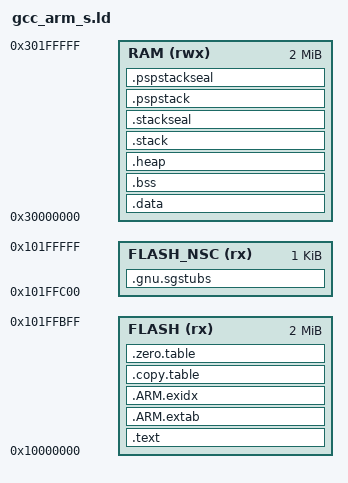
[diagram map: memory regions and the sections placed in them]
/*
 *
 * MIT License
 * Copyright (c) 2023 ARM Limited.
 *
 * SPDX-License-Identifier: MIT
 *
 * Permission is hereby granted, free of charge, to any person obtaining a copy
 * of this software and associated documentation files (the "Software"), to deal
 * in the Software without restriction, including without limitation the rights
 * to use, copy, modify, merge, publish, distribute, sublicense, and/or sell
 * copies of the Software, and to permit persons to whom the Software is
 * furnished to do so, subject to the following conditions:
 *
 * The above copyright notice and this permission notice shall be included in all
 * copies or substantial portions of the Software.
 *
 * THE SOFTWARE IS PROVIDED "AS IS", WITHOUT WARRANTY OF ANY KIND, EXPRESS OR
 * IMPLIED, INCLUDING BUT NOT LIMITED TO THE WARRANTIES OF MERCHANTABILITY,
 * FITNESS FOR A PARTICULAR PURPOSE AND NONINFRINGEMENT. IN NO EVENT SHALL THE
 * AUTHORS OR COPYRIGHT HOLDERS BE LIABLE FOR ANY CLAIM, DAMAGES OR OTHER
 * LIABILITY, WHETHER IN AN ACTION OF CONTRACT, TORT OR OTHERWISE, ARISING FROM,
 * OUT OF OR IN CONNECTION WITH THE SOFTWARE OR THE USE OR OTHER DEALINGS IN THE
 * SOFTWARE.
 *
 */

/*
 *-------- <<< Use Configuration Wizard in Context Menu >>> -------------------
 */

/*---------------------- Flash Configuration ----------------------------------
  <h> Flash Configuration
    <o0> Flash Base Address <0x0-0xFFFFFFFF:8>
    <o1> Flash Size (in Bytes) <0x0-0xFFFFFFFF:8>
  </h>
  -----------------------------------------------------------------------------*/
__ROM_BASE_S = 0x10000000;      
__ROM_SIZE_S = 0x001FFC00;      

__ROM_BASE_NSC =  0x101FFC00;      
__ROM_SIZE_NSC =  0x400;     

/*--------------------- Embedded RAM Configuration ----------------------------
  <h> RAM Configuration
    <o0> RAM Base Address    <0x0-0xFFFFFFFF:8>
    <o1> RAM Size (in Bytes) <0x0-0xFFFFFFFF:8>
  </h>
 -----------------------------------------------------------------------------*/
__RAM_BASE_S = 0x30000000;
__RAM_SIZE_S = 0x00200000;

/*--------------------- Stack / Heap Configuration ----------------------------
  <h> Stack / Heap Configuration
    <o0> Stack Size (in Bytes) <0x0-0xFFFFFFFF:8>
    <o1> Heap Size (in Bytes) <0x0-0xFFFFFFFF:8>
  </h>
  -----------------------------------------------------------------------------*/
__STACK_SIZE = 0x00000400;
__HEAP_SIZE  = 0x00000C00;
__PSP_STACK_SIZE = 0x00000400;


/*
 *-------------------- <<< end of configuration section >>> -------------------
 */

/* ARMv8-M stack sealing:
   to use ARMv8-M stack sealing set __STACKSEAL_SIZE to 8 otherwise keep 0
 */
__STACKSEAL_SIZE = 8;


MEMORY
{
  FLASH (rx)  : ORIGIN = __ROM_BASE_S, LENGTH = __ROM_SIZE_S
  FLASH_NSC (rx)  : ORIGIN = __ROM_BASE_NSC, LENGTH = __ROM_SIZE_NSC
  RAM   (rwx) : ORIGIN = __RAM_BASE_S, LENGTH = __RAM_SIZE_S
}

/* Linker script to place sections and symbol values. Should be used together
 * with other linker script that defines memory regions FLASH and RAM.
 * It references following symbols, which must be defined in code:
 *   Reset_Handler : Entry of reset handler
 *
 * It defines following symbols, which code can use without definition:
 *   __exidx_start
 *   __exidx_end
 *   __copy_table_start__
 *   __copy_table_end__
 *   __zero_table_start__
 *   __zero_table_end__
 *   __etext
 *   __data_start__
 *   __preinit_array_start
 *   __preinit_array_end
 *   __init_array_start
 *   __init_array_end
 *   __fini_array_start
 *   __fini_array_end
 *   __data_end__
 *   __bss_start__
 *   __bss_end__
 *   __end__
 *   end
 *   __HeapLimit
 *   __StackLimit
 *   __StackTop
 *   __stack
 *   __StackSeal      (only if ARMv8-M stack sealing is used)
 */
ENTRY(Reset_Handler)

SECTIONS
{
    .text :
    {
    
    KEEP(*(.vectors))
    *(.text*)

    KEEP(*(.init))
    KEEP(*(.fini))

    /* .ctors */
    *crtbegin.o(.ctors)
    *crtbegin?.o(.ctors)
    *(EXCLUDE_FILE(*crtend?.o *crtend.o) .ctors)
    *(SORT(.ctors.*))
    *(.ctors)

    /* .dtors */
    *crtbegin.o(.dtors)
    *crtbegin?.o(.dtors)
    *(EXCLUDE_FILE(*crtend?.o *crtend.o) .dtors)
    *(SORT(.dtors.*))
    *(.dtors)

    *(.rodata*)

    KEEP(*(.eh_frame*))
  } > FLASH

  /*
   * SG veneers:
   * All SG veneers are placed in the special output section .gnu.sgstubs. Its start address
   * must be set, either with the command line option С--section-startТ or in a linker script,
   * to indicate where to place these veneers in memory.
   */

  .gnu.sgstubs :
  {
    . = ALIGN(32);
    *(.gnu.sgstubs*)   /* Secure Gateway stubs */
  } > FLASH_NSC            /*FLASH*/
  
  Image$$ER_CMSE_VENEER$$Base = ADDR(.gnu.sgstubs);
  Image$$ER_CMSE_VENEER$$Limit = ADDR(.gnu.sgstubs) + SIZEOF(.gnu.sgstubs); 

  .ARM.extab :
  {
    *(.ARM.extab* .gnu.linkonce.armextab.*)
  } > FLASH

  __exidx_start = .;
  .ARM.exidx :
  {
    *(.ARM.exidx* .gnu.linkonce.armexidx.*)
  } > FLASH
  __exidx_end = .;

  .copy.table :
  {
    . = ALIGN(4);
    __copy_table_start__ = .;
    LONG (__etext)
    LONG (__data_start__)
    LONG (__data_end__ - __data_start__)
    /* Add each additional data section here */
    __copy_table_end__ = .;
  } > FLASH

  .zero.table :
  {
    . = ALIGN(4);
    __zero_table_start__ = .;
    /* Add each additional bss section here */
    __zero_table_end__ = .;
  } > FLASH

  /**
   * Location counter can end up 2byte aligned with narrow Thumb code but
   * __etext is assumed by startup code to be the LMA of a section in RAM
   * which must be 4byte aligned 
   */
  __etext = ALIGN (4);

  .data : AT (__etext)
  {
    __data_start__ = .;
    *(vtable)
    *(.data*)

    . = ALIGN(4);
    /* preinit data */
    PROVIDE_HIDDEN (__preinit_array_start = .);
    KEEP(*(.preinit_array))
    PROVIDE_HIDDEN (__preinit_array_end = .);

    . = ALIGN(4);
    /* init data */
    PROVIDE_HIDDEN (__init_array_start = .);
    KEEP(*(SORT(.init_array.*)))
    KEEP(*(.init_array))
    PROVIDE_HIDDEN (__init_array_end = .);


    . = ALIGN(4);
    /* finit data */
    PROVIDE_HIDDEN (__fini_array_start = .);
    KEEP(*(SORT(.fini_array.*)))
    KEEP(*(.fini_array))
    PROVIDE_HIDDEN (__fini_array_end = .);

    KEEP(*(.jcr*))
    . = ALIGN(4);
    /* All data end */
    __data_end__ = .;

  } > RAM

    .bss :
    {
        . = ALIGN(4);
        __bss_start__ = .;
        *(.bss*)
        *(COMMON)
        . = ALIGN(4);
        __bss_end__ = .;
    } > RAM

  .heap (COPY) :
  {
    . = ALIGN(8);
    __end__ = .;
    PROVIDE(end = .);
    . = . + __HEAP_SIZE;
    . = ALIGN(8);
    __HeapLimit = .;
  } > RAM

  .stack (ORIGIN(RAM) + LENGTH(RAM) - __STACK_SIZE - __STACKSEAL_SIZE - __PSP_STACK_SIZE - __STACKSEAL_SIZE) (COPY) :
  {
    . = ALIGN(8);
    __StackLimit = .;
    . = . + __STACK_SIZE;
    . = ALIGN(8);
    __StackTop = .;
  } > RAM
  PROVIDE(__stack = __StackTop);
  
  /* ARMv8-M stack sealing:
     to use ARMv8-M stack sealing uncomment '.stackseal' section
   */

  .stackseal (ORIGIN(RAM) + LENGTH(RAM) - __PSP_STACK_SIZE - __STACKSEAL_SIZE - __STACKSEAL_SIZE) (COPY) :
  {
    . = ALIGN(8);
    __StackSeal = .;
    . = . + 8;
    . = ALIGN(8);
  } > RAM

 .pspstack (ORIGIN(RAM) + LENGTH(RAM) - __PSP_STACK_SIZE - __STACKSEAL_SIZE) (COPY) :
  {
    . = ALIGN(8);
    __PSPStackLimit = .;
    . = . + __PSP_STACK_SIZE;
    . = ALIGN(8);
    __PSPStackTop = .;
  } > RAM
  
  Image$$PSP_STACK$$ZI$$Base = ADDR(.pspstack);
  Image$$PSP_STACK$$ZI$$Limit = ADDR(.pspstack) + SIZEOF(.pspstack);


 .pspstackseal (ORIGIN(RAM) + LENGTH(RAM) - __STACKSEAL_SIZE) (COPY) :
  {
    . = ALIGN(8);
    __PSPStackSeal = .;
    . = . + 8;
    . = ALIGN(8);
  } > RAM

 Image$$PSP_STACKSEAL$$Base = ADDR(.pspstackseal) + SIZEOF(.pspstackseal);

  /* Check if data + heap + stack exceeds RAM limit */
  ASSERT(__StackLimit >= __HeapLimit, "region RAM overflowed with stack")
}
